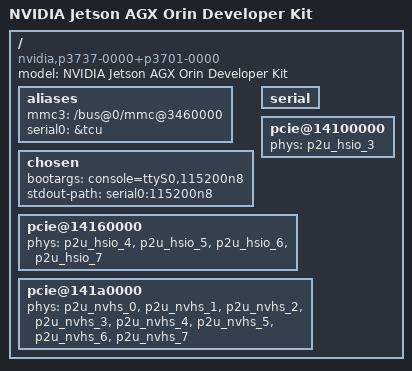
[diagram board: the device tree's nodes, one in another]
// SPDX-License-Identifier: GPL-2.0
/dts-v1/;

#include "tegra234-p3701-0000.dtsi"
#include "tegra234-p3737-0000.dtsi"

/ {
	model = "NVIDIA Jetson AGX Orin Developer Kit";
	compatible = "nvidia,p3737-0000+p3701-0000", "nvidia,p3701-0000", "nvidia,tegra234";

	aliases {
		mmc3 = "/bus@0/mmc@3460000";
		serial0 = &tcu;
	};

	chosen {
		bootargs = "console=ttyS0,115200n8";
		stdout-path = "serial0:115200n8";
	};

	serial {
		status = "okay";
	};

	pcie@14100000 {
		status = "okay";

		phys = <&p2u_hsio_3>;
		phy-names = "p2u-0";
	};

	pcie@14160000 {
		status = "okay";

		phys = <&p2u_hsio_4>, <&p2u_hsio_5>, <&p2u_hsio_6>,
		       <&p2u_hsio_7>;
		phy-names = "p2u-0", "p2u-1", "p2u-2", "p2u-3";
	};

	pcie@141a0000 {
		status = "okay";

		phys = <&p2u_nvhs_0>, <&p2u_nvhs_1>, <&p2u_nvhs_2>,
		       <&p2u_nvhs_3>, <&p2u_nvhs_4>, <&p2u_nvhs_5>,
		       <&p2u_nvhs_6>, <&p2u_nvhs_7>;
		phy-names = "p2u-0", "p2u-1", "p2u-2", "p2u-3", "p2u-4",
			    "p2u-5", "p2u-6", "p2u-7";
	};

};
